# apollo3 register map
Vendor: Ambiq Micro; Series: Apollo; File version: 1.0
CPU: CM4 r1p0, little endian, MPU, FPU, 3 interrupt priority bits
Registers are 32-bit, read-write, reset 0x0 unless marked. A register's access mark holds for its fields unless they carry their own. Offsets are from the block's base; [hi:lo] are bit positions; 'fields as' and 'values as' point back to an identical list.

## RSTGEN — MCU Reset Generator
Base 0x40000000
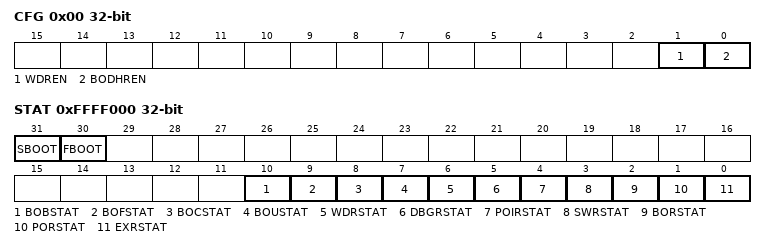
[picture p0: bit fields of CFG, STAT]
0x00 CFG — Configuration Register
  [1] WDREN — Watchdog Timer Reset Enable. NOTE: The WDT module must also be configured for WDT reset. This includes enabling the RESEN bit in WDTCFG register in Watch dog timer block.
  [0] BODHREN — Brown out high (2.1v) reset enable.
0x04 SWPOI — Software POI Reset
  [7:0] SWPOIKEY — 0x1B generates a software POI reset. This is a write-only register. Reading from this register will yield only all 0s.
    27=KEYVALUE (Writing 0x1B key value generates a software POI reset. value.)
0x08 SWPOR — Software POR Reset
  [7:0] SWPORKEY — 0xD4 generates a software POR reset.
    212=KEYVALUE (Writing 0xD4 key value generates a software POR reset. value.)
0x14 TPIURST — TPIU reset
  [0] TPIURST — Static reset for the TPIU. Write to '1' to assert reset to TPIU. Write to '0' to clear the reset.
0x200 INTEN — Reset Interrupt register: Enable
  [0] BODH — Enables an interrupt that triggers when VCC is below BODH level.
0x204 INTSTAT — Reset Interrupt register: Status
  fields as INTEN
0x208 INTCLR — Reset Interrupt register: Clear
  fields as INTEN
0x20C INTSET — Reset Interrupt register: Set
  fields as INTEN
0xFFFF000 STAT — Status Register (SBL)
  [31] SBOOT — Set when booting securely (SBL).
  [30] FBOOT — Set if current boot was initiated by soft reset and resulted in Fast Boot (SBL).
  [10] BOBSTAT — A BLE/Burst Regulator Brownout Event occurred (SBL).
  [9] BOFSTAT — A Memory Regulator Brownout Event occurred (SBL).
  [8] BOCSTAT — A Core Regulator Brownout Event occurred (SBL).
  [7] BOUSTAT — An Unregulated Supply Brownout Event occurred (SBL).
  [6] WDRSTAT — Reset was initiated by a Watchdog Timer Reset (SBL).
  [5] DBGRSTAT — Reset was a initiated by Debugger Reset (SBL).
  [4] POIRSTAT — Reset was a initiated by Software POI Reset (SBL).
  [3] SWRSTAT — Reset was a initiated by SW POR or AIRCR Reset (SBL).
  [2] BORSTAT — Reset was initiated by a Brown-Out Reset (SBL).
  [1] PORSTAT — Reset was initiated by a Power-On Reset (SBL).
  [0] EXRSTAT — Reset was initiated by an External Reset (SBL).

## RTC — Real Time Clock
Base 0x40004200
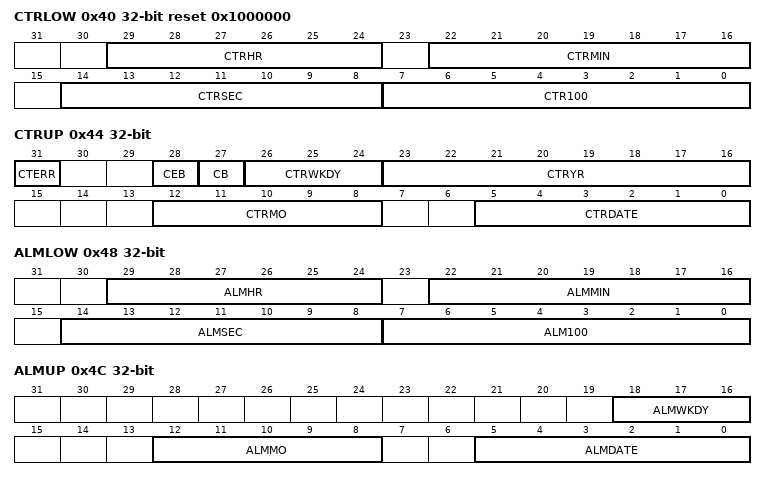
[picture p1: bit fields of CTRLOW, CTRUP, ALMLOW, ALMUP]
0x40 CTRLOW reset 0x1000000 — RTC Counters Lower
  [29:24] CTRHR — Hours Counter
  [22:16] CTRMIN — Minutes Counter
  [14:8] CTRSEC — Seconds Counter
  [7:0] CTR100 — 100ths of a second Counter
0x44 CTRUP — RTC Counters Upper
  [31] CTERR — Counter read error status. Error is triggered when software reads the lower word of the counters, and fails to read the upper counter within 1/100 second. This is because when the lower counter is read, the upper counter is held off from incrementing until it is read so that the full time stamp can be read.
    0=NOERR (No read error occurred value.); 1=RDERR (Read error occurred value.)
  [28] CEB — Century enable
    0=DIS (Disable the Century bit from changing value.); 1=EN (Enable the Century bit to change value.)
  [27] CB — Century
    0=Century is 2000s value; 1=1900_2100 (Century is 1900s/2100s value.)
  [26:24] CTRWKDY — Weekdays Counter
  [23:16] CTRYR — Years Counter
  [12:8] CTRMO — Months Counter
  [5:0] CTRDATE — Date Counter
0x48 ALMLOW — RTC Alarms Lower
  [29:24] ALMHR — Hours Alarm
  [22:16] ALMMIN — Minutes Alarm
  [14:8] ALMSEC — Seconds Alarm
  [7:0] ALM100 — 100ths of a second Alarm
0x4C ALMUP — RTC Alarms Upper
  [18:16] ALMWKDY — Weekdays Alarm
  [12:8] ALMMO — Months Alarm
  [5:0] ALMDATE — Date Alarm
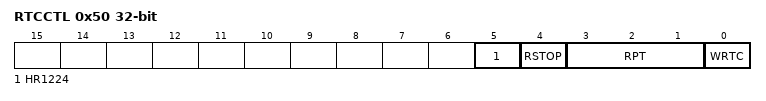
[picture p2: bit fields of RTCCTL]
0x50 RTCCTL — RTC Control Register
  [5] HR1224 — Hours Counter mode
    0=24HR (Hours in 24 hour mode value.); 1=12HR (Hours in 12 hour mode value.)
  [4] RSTOP — RTC input clock control
    0=RUN (Allow the RTC input clock to run value.); 1=STOP (Stop the RTC input clock value.)
  [3:1] RPT — Alarm repeat interval
    0=DIS (Alarm interrupt disabled value.); 1=YEAR (Interrupt every year value.); 2=MONTH (Interrupt every month value.); 3=WEEK (Interrupt every week value.); 4=DAY (Interrupt every day value.); 5=HR (Interrupt every hour value.); 6=MIN (Interrupt every minute value.); 7=SEC (Interrupt every second/10th/100th value.)
  [0] WRTC — Counter write control
    0=DIS (Counter writes are disabled value.); 1=EN (Counter writes are enabled value.)
0x100 INTEN — RTC Interrupt Register: Enable
  [0] ALM — RTC Alarm interrupt
0x104 INTSTAT — RTC Interrupt Register: Status
  [0] ALM — RTC Alarm interrupt
0x108 INTCLR — RTC Interrupt Register: Clear
  [0] ALM — RTC Alarm interrupt
0x10C INTSET — RTC Interrupt Register: Set
  [0] ALM — RTC Alarm interrupt
